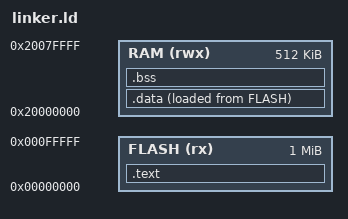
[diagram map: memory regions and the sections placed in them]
/* linker.ld */
MEMORY
{
    FLASH (rx) : ORIGIN = 0x00000000, LENGTH = 1M
    RAM (rwx)  : ORIGIN = 0x20000000, LENGTH = 512K
}

SECTIONS
{
    .text : {
        *(.vectors)
        *(.text)
        *(.text*)
        *(.rodata)
        *(.rodata*)
        . = ALIGN(4);
    } > FLASH

    .data : {
        _sdata = .;
        *(.data)
        *(.data*)
        . = ALIGN(4);
        _edata = .;
    } > RAM AT > FLASH

    .bss : {
        _sbss = .;
        *(.bss)
        *(.bss*)
        *(COMMON)
        . = ALIGN(4);
        _ebss = .;
    } > RAM
}
